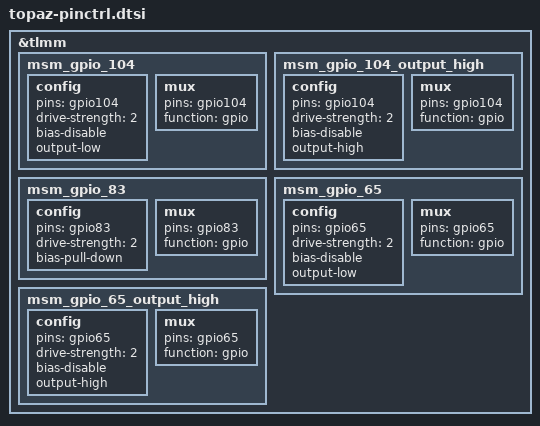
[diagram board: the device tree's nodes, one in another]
&tlmm {
	msm_gpio_104: msm_gpio_104 {
		config {
			pins = "gpio104";
			drive-strength = <2>;
			bias-disable;
			output-low;
		};

		mux {
			pins = "gpio104";
			function = "gpio";
		};
	};

	msm_gpio_104_output_high: msm_gpio_104_output_high {
		config {
			pins = "gpio104";
		    drive-strength = <2>;
			bias-disable;
			output-high;
		};

		mux {
			pins = "gpio104";
			function = "gpio";
		};
	};

	msm_gpio_83: msm_gpio_83 {
		config {
			pins = "gpio83";
			drive-strength = <2>;
			bias-pull-down;
		};

		mux {
			pins = "gpio83";
			function = "gpio";
		};

	};

	msm_gpio_65: msm_gpio_65 {
		config {
			pins = "gpio65";
			drive-strength = <2>;
			bias-disable;
			output-low;
		};

		mux {
			pins = "gpio65";
			function = "gpio";
		};
	};

	msm_gpio_65_output_high: msm_gpio_65_output_high {
		config {
			pins = "gpio65";
			drive-strength = <2>;
			bias-disable;
			output-high;
		};

		mux {
			pins = "gpio65";
			function = "gpio";
		};
	};
};
